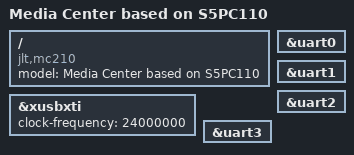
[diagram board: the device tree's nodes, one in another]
/*
 * Samsung's S5PV210 SoC device tree source
 *
 * Copyright (c) 2013-2014 Samsung Electronics, Co. Ltd.
 *
 * Mateusz Krawczuk <m.krawczuk@partner.samsung.com>
 * Tomasz Figa <t.figa@samsung.com>
 *
 * Board device tree source for Torbreck board.
 *
 * NOTE: This file is completely based on original board file for mach-torbreck
 * available in Linux 3.15 and intends to provide equivalent level of hardware
 * support. Due to lack of hardware, _no_ testing has been performed.
 *
 * This program is free software; you can redistribute it and/or modify
 * it under the terms of the GNU General Public License version 2 as
 * published by the Free Software Foundation.
 */

/dts-v1/;
#include <dt-bindings/input/input.h>
#include "s5pv210.dtsi"

/ {
	model = "Media Center based on S5PC110";
	compatible = "jlt,mc210", "samsung,s5pv210";
};

&xusbxti {
	clock-frequency = <24000000>;
};

&uart0 {
	status = "okay";
};

&uart1 {
	status = "okay";
};

&uart2 {
	status = "okay";
};

&uart3 {
	status = "okay";
};
